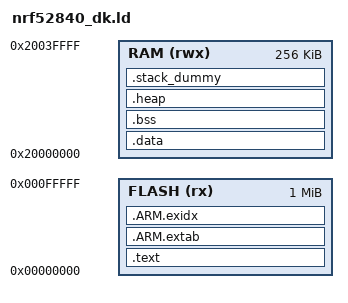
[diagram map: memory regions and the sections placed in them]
/* Linker script for nRF52840 DK */

MEMORY
{
  FLASH (rx) : ORIGIN = 0x00000000, LENGTH = 0x100000  /* 1MB */
  RAM (rwx) : ORIGIN = 0x20000000, LENGTH = 0x40000    /* 256KB */
}

SECTIONS
{
    .text :
    {
        KEEP(*(.isr_vector))
        *(.text*)
        KEEP(*(.init))
        KEEP(*(.fini))
        *(.rodata*)
    } > FLASH

    .ARM.extab :
    {
        *(.ARM.extab* .gnu.linkonce.armextab.*)
    } > FLASH

    .ARM.exidx :
    {
        __exidx_start = .;
        *(.ARM.exidx* .gnu.linkonce.armexidx.*)
        __exidx_end = .;
    } > FLASH

    __etext = .;

    .data : AT (__etext)
    {
        __data_start__ = .;
        *(vtable)
        *(.data*)
        __data_end__ = .;
    } > RAM

    .bss :
    {
        . = ALIGN(4);
        __bss_start__ = .;
        *(.bss*)
        *(COMMON)
        . = ALIGN(4);
        __bss_end__ = .;
    } > RAM

    .heap (COPY):
    {
        __HeapBase = .;
        __end__ = .;
        PROVIDE(end = .);
        KEEP(*(.heap*))
        __HeapLimit = .;
    } > RAM

    .stack_dummy (COPY):
    {
        KEEP(*(.stack*))
    } > RAM

    __StackTop = ORIGIN(RAM) + LENGTH(RAM);
    __StackLimit = __StackTop - SIZEOF(.stack_dummy);
    PROVIDE(__stack = __StackTop);
}
